# MK50D10 register map
Vendor: Freescale Semiconductor, Inc.; Series: Kinetis_K; File version: 1.6
CPU: CM4 r0p1, little endian, no MPU, no FPU, VTOR, 4 interrupt priority bits
Registers are 8-bit, read-write, reset 0x0 unless marked. A register's access mark holds for its fields unless they carry their own. Offsets are from the block's base; [hi:lo] are bit positions; {n}, {i} and the like mark numbered series.

## FB — FlexBus external bus interface
Base 0x4000C000; register names take the prefix FB_
{0x0+0xC*i} CSAR{i} (i=0..5) 32-bit — Chip Select Address Register
  [31:16] BA — Base Address
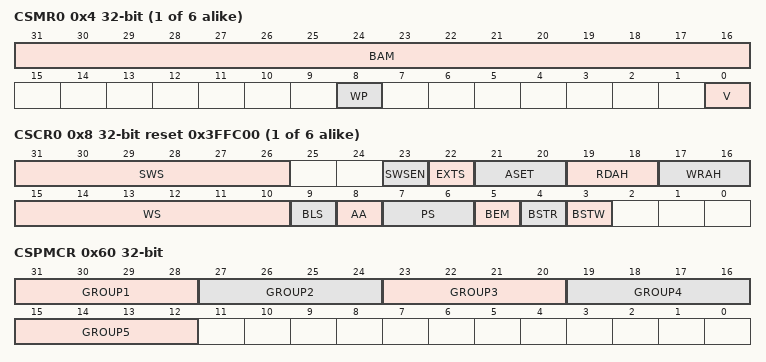
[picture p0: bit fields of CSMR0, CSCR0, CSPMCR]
{0x4+0xC*i} CSMR{i} (i=0..5) 32-bit — Chip Select Mask Register
  [31:16] BAM — Base Address Mask
    0=The corresponding address bit in CSAR is used in the chip-select decode; 1=The corresponding address bit in CSAR is a don't care in the chip-select decode
  [8] WP — Write Protect
    0=Write accesses are allowed; 1=Write accesses are not allowed. Attempting to write to the range of addresses for which the WP bit is set results in a bus error termination of the internal cycle and no external cycle.
  [0] V — Valid
    0=Chip-select is invalid; 1=Chip-select is valid
{0x8+0xC*i} CSCR{i} (i=0..5) 32-bit reset 0x3FFC00 — Chip Select Control Register
  [31:26] SWS — Secondary Wait States
  [23] SWSEN — Secondary Wait State Enable
    0=Disabled. A number of wait states (specified by WS) are inserted before an internal transfer acknowledge is generated for all transfers.; 1=Enabled. A number of wait states (specified by SWS) are inserted before an internal transfer acknowledge is generated for burst transfer secondary terminations.
  [22] EXTS — Extended Transfer Start/Extended Address Latch Enable Controls how long FB_TS /FB_ALE is asserted.
    0=Disabled. FB_TS /FB_ALE asserts for one bus clock cycle.; 1=Enabled. FB_TS /FB_ALE remains asserted until the first positive clock edge after FB_CSn asserts.
  [21:20] ASET — Address Setup
    0=Assert FB_CSn on the first rising clock edge after the address is asserted (default for all but FB_CS0 ); 1=Assert FB_CSn on the second rising clock edge after the address is asserted; 2=Assert FB_CSn on the third rising clock edge after the address is asserted; 3=Assert FB_CSn on the fourth rising clock edge after the address is asserted (default for FB_CS0 )
  [19:18] RDAH — Read Address Hold or Deselect
    0=When AA is 0b, 1 cycle. When AA is 1b, 0 cycles.; 1=When AA is 0b, 2 cycles. When AA is 1b, 1 cycle.; 2=When AA is 0b, 3 cycles. When AA is 1b, 2 cycles.; 3=When AA is 0b, 4 cycles. When AA is 1b, 3 cycles.
  [17:16] WRAH — Write Address Hold or Deselect
    0=1 cycle (default for all but FB_CS0 ); 1=2 cycles; 2=3 cycles; 3=4 cycles (default for FB_CS0 )
  [15:10] WS — Wait States
  [9] BLS — Byte-Lane Shift
    0=Not shifted. Data is left-aligned on FB_AD.; 1=Shifted. Data is right-aligned on FB_AD.
  [8] AA — Auto-Acknowledge Enable
    0=Disabled. No internal transfer acknowledge is asserted and the cycle is terminated externally.; 1=Enabled. Internal transfer acknowledge is asserted as specified by WS.
  [7:6] PS — Port Size
    0=32-bit port size. Valid data is sampled and driven on FB_D[31:0].; 1=8-bit port size. Valid data is sampled and driven on FB_D[31:24] when BLS is 0b, or FB_D[7:0] when BLS is 1b.; 2=16-bit port size. Valid data is sampled and driven on FB_D[31:16] when BLS is 0b, or FB_D[15:0] when BLS is 1b.; 3=16-bit port size. Valid data sampled and driven on FB_D[31:16] when BLS is 0b, or FB_D[15:0] when BLS is 1b.
  [5] BEM — Byte-Enable Mode
    0=FB_BE is asserted for data write only; 1=FB_BE is asserted for data read and write accesses
  [4] BSTR — Burst-Read Enable
    0=Disabled. Data exceeding the specified port size is broken into individual, port-sized, non-burst reads. For example, a 32-bit read from an 8-bit port is broken into four 8-bit reads.; 1=Enabled. Enables data burst reads larger than the specified port size, including 32-bit reads from 8- and 16-bit ports, 16-bit reads from 8-bit ports, and line reads from 8, 16-, and 32-bit ports.
  [3] BSTW — Burst-Write Enable
    0=Disabled. Data exceeding the specified port size is broken into individual, port-sized, non-burst writes. For example, a 32-bit write to an 8-bit port takes four byte writes.; 1=Enabled. Enables burst write of data larger than the specified port size, including 32-bit writes to 8 and 16-bit ports, 16-bit writes to 8-bit ports, and line writes to 8-, 16-, and 32-bit ports.
0x60 CSPMCR 32-bit — Chip Select port Multiplexing Control Register
  [31:28] GROUP1 — FlexBus Signal Group 1 Multiplex control
    0=FB_ALE; 1=FB_CS1; 2=FB_TS
  [27:24] GROUP2 — FlexBus Signal Group 2 Multiplex control
    0=FB_CS4; 1=FB_TSIZ0; 2=FB_BE_31_24
  [23:20] GROUP3 — FlexBus Signal Group 3 Multiplex control
    0=FB_CS5; 1=FB_TSIZ1; 2=FB_BE_23_16
  [19:16] GROUP4 — FlexBus Signal Group 4 Multiplex control
    0=FB_TBST; 1=FB_CS2; 2=FB_BE_15_8
  [15:12] GROUP5 — FlexBus Signal Group 5 Multiplex control
    0=FB_TA; 1=FB_CS3 . You must also write 1b to CSCR[AA].; 2=FB_BE_7_0 . You must also write 1b to CSCR[AA].
